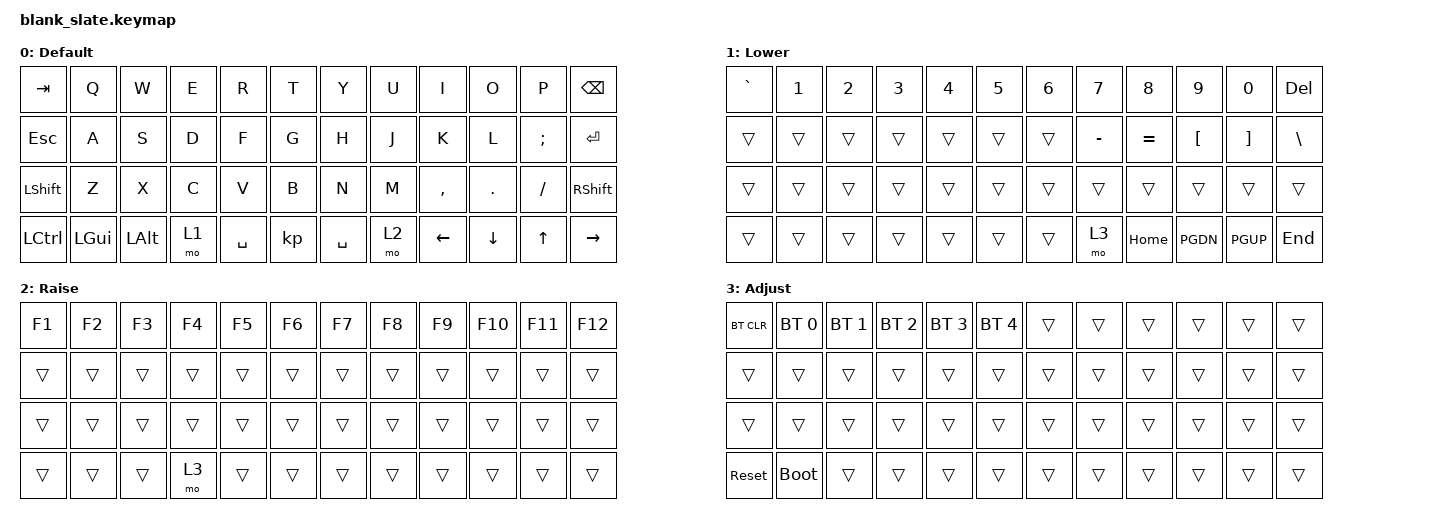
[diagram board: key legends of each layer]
#include <behaviors.dtsi>
#include <dt-bindings/zmk/keys.h>
#include <dt-bindings/zmk/bt.h>

/ {
    keymap {
        compatible = "zmk,keymap";
        
        default_layer {
            display-name = "Default";
            bindings = <
                &kp TAB    &kp Q    &kp W    &kp E    &kp R    &kp T    &kp Y    &kp U    &kp I    &kp O    &kp P    &kp BSPC
                &kp ESC    &kp A    &kp S    &kp D    &kp F    &kp G    &kp H    &kp J    &kp K    &kp L    &kp SEMI &kp ENTER
                &kp LSHFT  &kp Z    &kp X    &kp C    &kp V    &kp B    &kp N    &kp M    &kp COMMA &kp DOT &kp SLASH &kp RSHFT
                &kp LCTRL  &kp LGUI &kp LALT &mo 1    &kp SPACE &kp         &kp SPACE &mo 2 &kp LEFT &kp DOWN &kp UP   &kp RIGHT
            >;
        };

        lower_layer {
            display-name = "Lower";
            bindings = <
                &kp GRAVE  &kp N1   &kp N2   &kp N3   &kp N4   &kp N5   &kp N6   &kp N7   &kp N8   &kp N9   &kp N0   &kp DEL
                &trans     &trans   &trans   &trans   &trans   &trans   &trans   &kp MINUS &kp EQUAL &kp LBKT &kp RBKT &kp BSLH
                &trans     &trans   &trans   &trans   &trans   &trans   &trans   &trans   &trans   &trans   &trans   &trans
                &trans     &trans   &trans   &trans   &trans   &trans   &trans   &mo 3    &kp HOME &kp PGDN &kp PGUP &kp END
            >;
        };

        raise_layer {
            display-name = "Raise";
            bindings = <
                &kp F1     &kp F2   &kp F3   &kp F4   &kp F5   &kp F6   &kp F7   &kp F8   &kp F9   &kp F10  &kp F11  &kp F12
                &trans     &trans   &trans   &trans   &trans   &trans   &trans   &trans   &trans   &trans   &trans   &trans
                &trans     &trans   &trans   &trans   &trans   &trans   &trans   &trans   &trans   &trans   &trans   &trans
                &trans     &trans   &trans   &mo 3    &trans   &trans   &trans   &trans   &trans   &trans   &trans   &trans
            >;
        };

        adjust_layer {
            display-name = "Adjust";
            bindings = <
                &bt BT_CLR &bt BT_SEL 0 &bt BT_SEL 1 &bt BT_SEL 2 &bt BT_SEL 3 &bt BT_SEL 4 &trans &trans &trans &trans &trans &trans
                &trans     &trans   &trans   &trans   &trans   &trans   &trans   &trans   &trans   &trans   &trans   &trans
                &trans     &trans   &trans   &trans   &trans   &trans   &trans   &trans   &trans   &trans   &trans   &trans
                &sys_reset &bootloader &trans &trans  &trans   &trans   &trans   &trans   &trans   &trans   &trans   &trans
            >;
        };
    };
};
